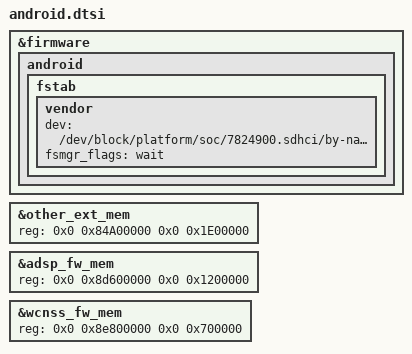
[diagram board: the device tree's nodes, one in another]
&firmware {
	android {
		/delete-node/ vbmeta;
		fstab {
			vendor {
				dev = "/dev/block/platform/soc/7824900.sdhci/by-name/cust";
				fsmgr_flags = "wait";
			};
		};
	};
};

&other_ext_mem {
	reg = <0x0 0x84A00000 0x0 0x1E00000>;
};
&adsp_fw_mem {
	reg = <0x0 0x8d600000 0x0 0x1200000>;
};
&wcnss_fw_mem {
	reg = <0x0 0x8e800000 0x0 0x700000>;
};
